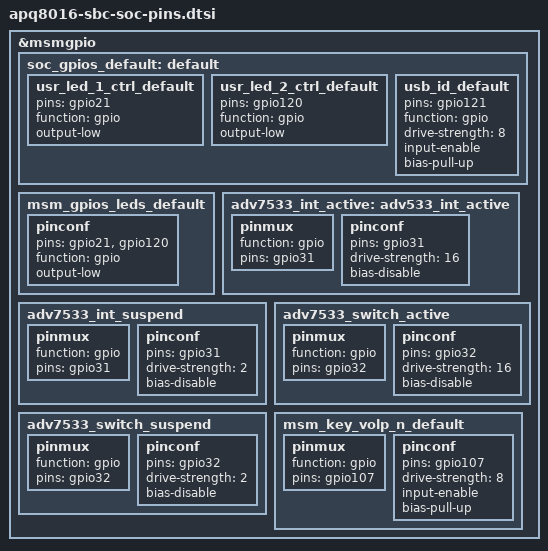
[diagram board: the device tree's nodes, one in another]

#include <dt-bindings/gpio/gpio.h>

&msmgpio {

	soc_gpios_default: default {
		usr_led_1_ctrl_default: usr_led_1_ctrl_default {
			pins = "gpio21";
			function = "gpio";
			output-low;
		};
		usr_led_2_ctrl_default: usr_led_2_ctrl_default {
			pins = "gpio120";
			function = "gpio";
			output-low;
		};

		usb_id_default: usb_id_default {
			pins = "gpio121";
			function = "gpio";
			drive-strength = <8>;
			input-enable;
			bias-pull-up;
		};
	};

	msm_gpios_leds_default: msm_gpios_leds_default {
		pinconf {
			pins = "gpio21", "gpio120";
			function = "gpio";
			output-low;
		};
	};

	adv7533_int_active: adv533_int_active {
		pinmux {
			function = "gpio";
			pins = "gpio31";
		};
		pinconf {
			pins = "gpio31";
			drive-strength = <16>;
			bias-disable;
		};
	};

	adv7533_int_suspend: adv7533_int_suspend {
		pinmux {
			function = "gpio";
			pins = "gpio31";
		};
		pinconf {
			pins = "gpio31";
			drive-strength = <2>;
			bias-disable;
		};
	};

	adv7533_switch_active: adv7533_switch_active {
		pinmux {
			function = "gpio";
			pins = "gpio32";
		};
		pinconf {
			pins = "gpio32";
			drive-strength = <16>;
			bias-disable;
		};
	};

	adv7533_switch_suspend: adv7533_switch_suspend {
		pinmux {
			function = "gpio";
			pins = "gpio32";
		};
		pinconf {
			pins = "gpio32";
			drive-strength = <2>;
			bias-disable;
		};
	};

	msm_key_volp_n_default: msm_key_volp_n_default {
		pinmux {
			function = "gpio";
			pins = "gpio107";
		};
		pinconf {
			pins = "gpio107";
			drive-strength = <8>;
			input-enable;
			bias-pull-up;
		};
	};
};
